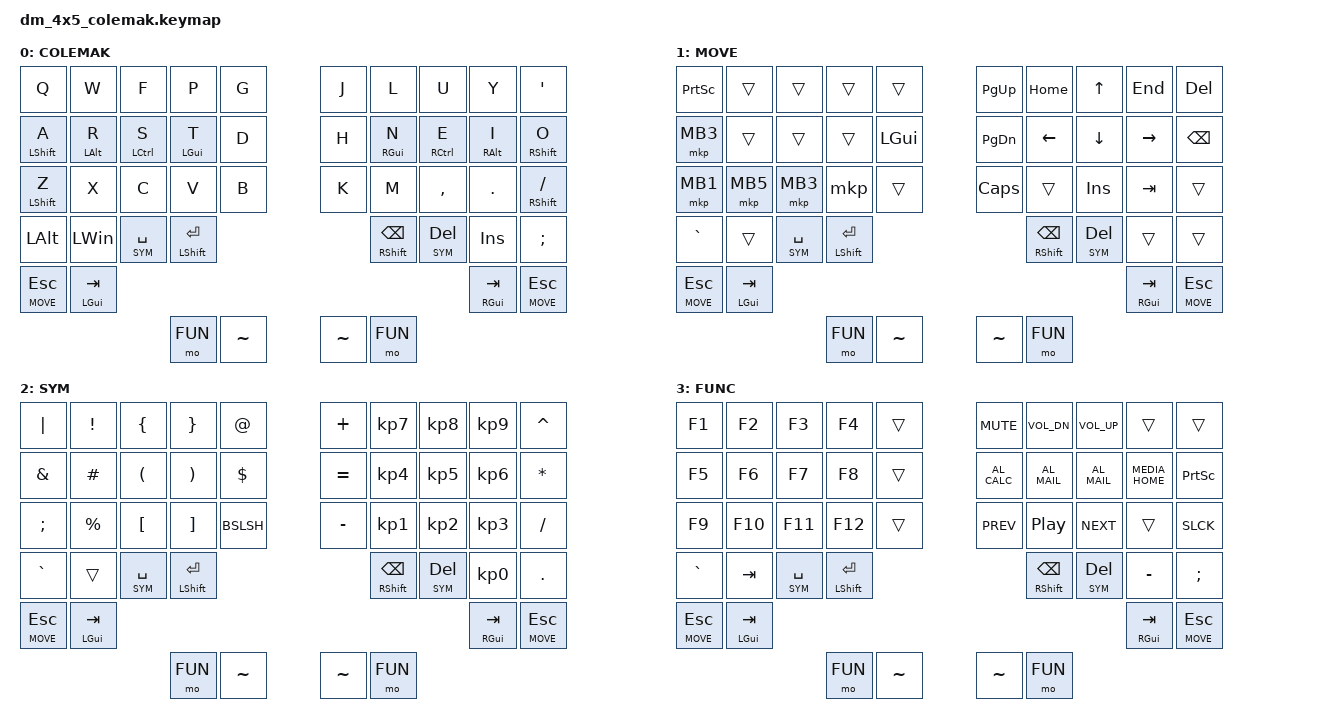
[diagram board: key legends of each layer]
/*
 * Copyright (c) 2020 The ZMK Contributors
 *
 * SPDX-License-Identifier: MIT
 */

#include <behaviors.dtsi>
#include <dt-bindings/zmk/keys.h>
#include <dt-bindings/zmk/bt.h>
#include <dt-bindings/zmk/outputs.h>
#include <dt-bindings/zmk/ext_power.h>
#include <dt-bindings/zmk/mouse.h>

#define BASE    0
#define MOVE    1
#define SYM     2
#define FUNC    3

&lt {
    tapping-term-ms = <240>;
    flavor = "tap-preferred";
    quick-tap-ms = <150>;
    require-prior-idle-ms = <10>;
};

&mt {
    tapping-term-ms = <250>;
    flavor = "tap-preferred";
    require-prior-idle-ms = <250>;
};

/ {
	keymap {
		compatible = "zmk,keymap";
/* BASE (COLEMAK)
 * note the usage of modifiers on the home row
 * ,----------------------------------,                                           ,----------------------------------,
 * |   q  |   w  |   f  |   p  |   g  |                                           |   j  |   l  |   u  |   y  |   '  |
 * |------+------+------+------+------|                                           |-------------+------+------+------|
 * |   a  |   r  |   s  |   t  |   d  |                                           |   h  |   n  |   e  |   i  |   o  |
 * | shft |  alt | ctrl |  gui |      |                                           |      | gui  | ctrl |  alt | shft |
 * |------+------+------+------+------|                                           |------|------+------+------+------+
 * |   z  |   x  |   c  |   v  |   b  |                                           |   k  |   m  |   ,  |   .  |   /  |
 * | shft |      |      |      |      |                                           |      |      |      |      | shft |
 * '------+------+------+-------------'                                           '-------------+------+------+------+
 *               |  alt | lwin |                                                         |insert|   ;  |
 *               '------+------'-------------,                             ,-------------'------+------'
 *                             | space| enter|                             |bckspc| del  |
 *                             | _sym | shift|                             |shift | _sym |
 *                             '------+------'                             '------+------'
 *                                           '------+------' '------+------'
 *                                           | esc  | tab  | | tab  | esc  |
 *                                           | _move| gui  | | gui  |_move |
 *                                           '------+------' '------+------'
 *                                           | _fn  |  ~   | |  ~   |  _fn |
 *                                           '------+------' '------+------'
 */
		BASE {
			display-name = "COLEMAK";

			bindings = <   
&kp        Q  &kp      W  &kp       F      &kp P &kp G                      &kp J       &kp L       &kp U      &kp Y   &kp APOS     
&mt LSHIFT A  &mt LALT R  &mt LCTRL S &mt LGUI T &kp D                      &kp H  &mt RGUI N &mt RCTRL E &mt RALT I &mt RSHIFT O  
&mt LSHIFT Z  &kp      X  &kp       C      &kp V &kp B                      &kp K       &kp M &kp COMMA &kp DOT &mt RSHIFT FSLH
       &kp LALT &kp LWIN  &lt SYM SPACE &mt LSHIFT ENTER     &mt RSHIFT BSPC  &mt SYM DEL      &kp INS &kp SEMI
                      &lt MOVE ESC &mt LGUI TAB           &mt RGUI TAB &lt MOVE ESC 
					  &mo FUN  &kp TILDE          &kp TILDE &mo FUN
			>;
		};

/* MOVE a movement layer inspired by Dreymar's bag of keyboard tricks (from Colemak forum), sadly mouse movements aren't in ZMK yet
 * ,----------------------------------,                                           ,----------------------------------,
 * | PScr | WhUP | MsUP | WhDN | WhUP |                                           |   ⤒  | Home |   ↑  | End  | Del  |
 * |------+------+------+------+------|                                           |-------------+------+------+------|
 * | BTN3 |MsLEFT| MsDN |MsRIGHT| GUI |                                           |   ⤓  |   ←  |   ↓  |   →  | Bsp  |
 * |------+------+------+------+------|                                           |------|------+------+------+------|
 * | BTN1 | BTN5 | BTN2 |  BTN3| WhDN |                                           | Caps |      |Insert| Tab  |      |
 * '------+------+------+-------------,                                           ,-------------+------+------+------'
 *               |   `  |      |                                                         |      |      |
 *               '------+------'-------------'                             '-------------'------+------'
 *                             | Space| Enter|                             |BckSpc| Del  |
 *                             | _SYM | Shift|                             |Shift | _SYM |
 *                             '------+------'                             '------+------'
 *                                           '------+------' '------+------'
 *                                           | Esc  | Tab  | |  Tab |  Esc |
 *                                           | _MOVE|      | |      |_MOVE |
 *                                           '------+------' '------+------'
 *                                           | _FN  |  ~   | |   ~  |  _FN |
 *                                           '------+------' '------+------'
 */

		MOVE {
			display-name = "MOVE";

			bindings = <
&kp PSCRN &trans &trans &trans &trans                                        &kp PG_UP &kp HOME &kp UP &kp END &kp DEL
&mkp MB3  &trans &trans &trans &kp LGUI                                      &kp PG_DN &kp LEFT &kp DOWN &kp RIGHT &kp BSPC
&mkp MB1  &mkp MB5 &mkp MB3 &mkp &trans                                      &kp CAPS &trans &kp INS &kp TAB &trans
                   &kp GRAVE &trans &lt SYM SPACE &mt LSHIFT ENTER     &mt RSHIFT BSPC  &mt SYM DEL &trans &trans
                      &lt MOVE ESC &mt LGUI TAB           &mt RGUI TAB &lt MOVE ESC 
					  &mo FUN  &kp TILDE          &kp TILDE &mo FUN
			>;

		};

/* SYM - a symbol layer, uses pairs of various brackets on left half and NumPad numbers on right half
 * ,----------------------------------,                                    ,----------------------------------,
 * |   |  |   !  |   {  |   }  |   @  |                                    |   +  |   7  |   8  |   9  |   ^  |
 * |------+------+------+------+------|                                    |-------------+------+------+------|
 * |   &  |   #  |   (  |   )  |   $  |                                    |   =  |   4  |   5  |   6  |   *  |
 * |------+------+------+------+------|                                    |------|------+------+------+------|
 * |   ;  |   %  |   [  |   ]  |   \  |                                    |   -  |   1  |   2  |   3  |   /  |
 * '------+------+------+-------------,                                    ,-------------+------+------+------'
 *               |   `  |      |                                                         |   0  |   .  |
 *               '------+------'-------------'                             '-------------'------+------'
 *                             | Space| Enter|                             |BckSpc| Del  |
 *                             | _SYM | Shift|                             |Shift | _SYM |
 *                             '------+------'                             '------+------'
 *                                           '------+------' '------+------'
 *                                           | Esc  | Tab  | |  Tab |  Esc |
 *                                           | _MOVE|      | |      |_MOVE |
 *                                           '------+------' '------+------'
 *                                           | _FN  |  ~   | |   ~  |  _FN |
 *                                           '------+------' '------+------'
 */
        SYM {
			display-name = "SYM";
			bindings = <
&kp PIPE &kp EXCL &kp LBRC &kp RBRC &kp AT                              &kp PLUS &kp KP_N7 &kp KP_N8 &kp KP_N9 &kp CARET
&kp AMPS &kp HASH &kp LPAR &kp RPAR &kp DLLR                            &kp EQUAL &kp KP_N4 &kp KP_N5 &kp KP_N6 &kp STAR
&kp SEMI &kp PRCNT &kp LBKT &kp RBKT &kp BSLSH                          &kp MINUS &kp KP_N1 &kp KP_N2 &kp KP_N3 &kp FSLH
                   &kp GRAVE &trans   &lt SYM SPACE &mt LSHIFT ENTER     &mt RSHIFT BSPC  &mt SYM DEL &kp KP_N0 &kp DOT
                      &lt MOVE ESC &mt LGUI TAB           &mt RGUI TAB &lt MOVE ESC 
					  &mo FUN  &kp TILDE          &kp TILDE &mo FUN
			>;
		};

/* FUNC - Function keys and assorted media controls
 * ,----------------------------------,                                    ,----------------------------------,
 * |  F1  |  F2  |  F3  |   F4 |      |                                    |   🔇 |  🔉  |   🔊 |      |      |
 * |------+------+------+------+------|                                    |-------------+------+------+------|
 * |   F5 |  F6  |  F7  |   F8 |      |                                    |   🖩  |  📧  |  🖳   |  🏡  |Pr.Scr|
 * |------+------+------+------+------|                                    |------|------+------+------+------|
 * |   F9 |   F10| F11  |  F12 |      |                                    |  ⏮️  |  ⏯️  |  ⏭️  |      |ScrlLk|
 * '------+------+------+-------------,                                    ,-------------+------+------+------'
 *               |   `  | Tab  |                                                         |   -  |   ;  |
 *               '------+------'-------------'                             '-------------'------+------'
 *                             | Space| Enter|                             |BckSpc| Del  |
 *                             | _SYM | Shift|                             |Shift | _SYM |
 *                             '------+------'                             '------+------'
 *                                           '------+------' '------+------'
 *                                           | Esc  | Tab  | |  Tab |  Esc |
 *                                           | _MOVE|      | |      |_MOVE |
 *                                           '------+------' '------+------'
 *                                           | _FN  |  ~   | |   ~  |  _FN |
 *                                           '------+------' '------+------'
 *
 */

		FUNC {
			display-name = "FUNC";
			bindings = <
&kp F1 &kp F2 &kp F3 &kp F4 &trans                                &kp C_MUTE &kp C_VOL_DN &kp C_VOL_UP &trans &trans
&kp F5 &kp F6 &kp F7 &kp F8 &trans                                &kp C_AL_CALC &kp C_AL_MAIL &kp C_AL_MAIL &kp C_MEDIA_HOME &kp PSCRN
&kp F9 &kp F10 &kp F11 &kp F12 &trans                             &kp C_PREV &kp C_PP &kp C_NEXT &trans &SLCK
       &kp GRAVE &kp TAB 	&lt SYM SPACE &mt LSHIFT ENTER     &mt RSHIFT BSPC  &mt SYM DEL 	&kp MINUS &kp SEMI
	                         &lt MOVE ESC &mt LGUI TAB           &mt RGUI TAB &lt MOVE ESC 
					  &mo FUN  &kp TILDE          &kp TILDE &mo FUN
			>;
		};

	};
};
